# IA_EDMA register map
Vendor: Texas Instruments
Peripheral module from a debugger description file (folder omap34xx).
Registers are 32-bit, access per field, reset 0x0 unless marked. A register's access mark holds for its fields unless they carry their own. Offsets are as the file gives them; lines under a group give offsets from that group; [hi:lo] are bit positions; {n}, {i} and the like mark numbered series; 'fields as' and 'values as' point back to an identical list; <NAME> marks a mode.

## IA_EDMA
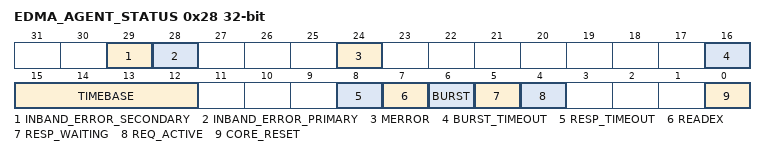
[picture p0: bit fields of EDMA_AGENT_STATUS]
0x28 EDMA_AGENT_STATUS — Agent Status Register
  [29] INBAND_ERROR_SECONDARY rw — Error Status for in-band errors with MErrSteer indicating a secondary error.
    0=INBAND_ERROR_SECONDARY_0_r (No in-band error received); 0=INBAND_ERROR_SECONDARY_0_w (Ignored); 1=INBAND_ERROR_SECONDARY_1_r (In-band error received); 1=INBAND_ERROR_SECONDARY_1_w (Clear in-band error)
  [28] INBAND_ERROR_PRIMARY rw — Error Status for in-band errors with MErrSteer indicating Primary Error
    0=INBAND_ERROR_PRIMARY_0_r (No in-band error received); 0=INBAND_ERROR_PRIMARY_0_w (Ignored); 1=INBAND_ERROR_PRIMARY_1_r (In-band error received); 1=INBAND_ERROR_PRIMARY_1_w (Clear in-band error)
  [24] MERROR ro — MError assertion detected
  [16] BURST_TIMEOUT ro — Status of open burst and
  [15:12] TIMEBASE ro — Observation of timebase signals for internal verification
  [8] RESP_TIMEOUT ro — Response timeout status
  [7] READEX ro — Status of ReadEx/Write
  [6] BURST ro — Status of open burst
  [5] RESP_WAITING ro — Responses waiting
  [4] REQ_ACTIVE ro — Requests outstanding
  [0] CORE_RESET ro — Reset input from core interface
